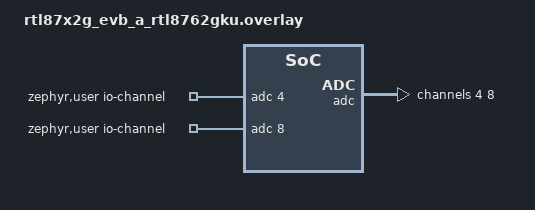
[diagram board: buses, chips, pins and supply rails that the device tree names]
/*
 * Copyright (c) 2026, Realtek Semiconductor Corporation
 *
 * SPDX-License-Identifier: Apache-2.0
 */

/ {
	zephyr,user {
		io-channels = <&adc 4>, <&adc 8>;
	};
};

&adc {
	pinctrl-0 = <&adc_default>;
	pinctrl-names = "default";
	#address-cells = <1>;
	#size-cells = <0>;
	status = "okay";

	channel@4 {
		reg = <4>;
		zephyr,gain = "ADC_GAIN_1";
		zephyr,reference = "ADC_REF_INTERNAL";
		zephyr,acquisition-time = <ADC_ACQ_TIME_DEFAULT>;
		zephyr,resolution = <12>;
	};

	channel@8 {
		reg = <8>;
		zephyr,gain = "ADC_GAIN_1";
		zephyr,reference = "ADC_REF_INTERNAL";
		zephyr,acquisition-time = <ADC_ACQ_TIME_DEFAULT>;
		zephyr,resolution = <12>;
	};
};

&pinctrl {
	adc_default: adc_default {
		group1 {
			psels = <BEE_PSEL(SW_MODE, P2_0)>;
			output-disable;
			bias-pull-down;
		};
	};
};
